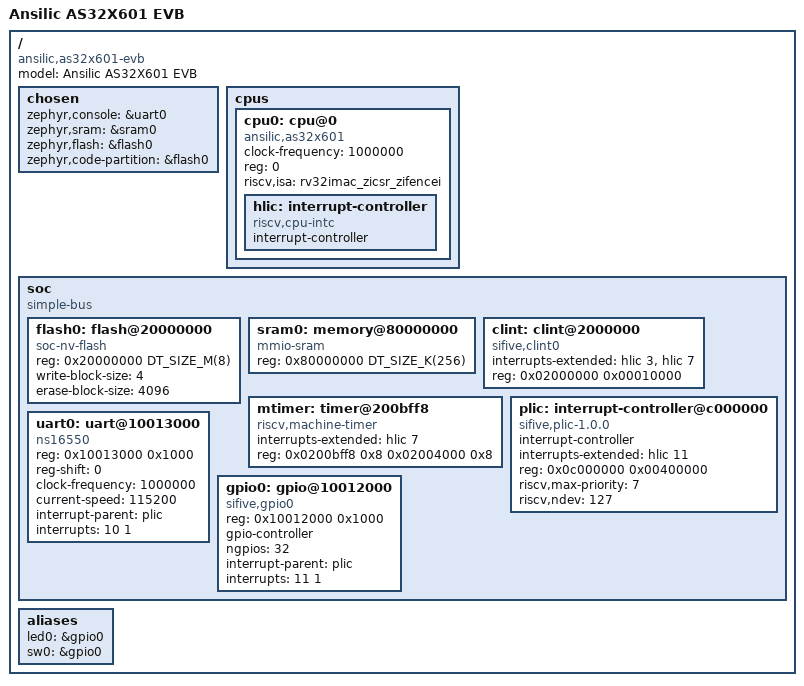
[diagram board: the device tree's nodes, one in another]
/dts-v1/;

#include <mem.h>

/ {
	model = "Ansilic AS32X601 EVB";
	compatible = "ansilic,as32x601-evb";

	#address-cells = <1>;
	#size-cells = <1>;

	chosen {
		zephyr,console = &uart0;
		zephyr,sram = &sram0;
		zephyr,flash = &flash0;
		zephyr,code-partition = &flash0;
	};

	cpus {
		#address-cells = <1>;
		#size-cells = <0>;

		cpu0: cpu@0 {
			clock-frequency = <1000000>;
			compatible = "ansilic,as32x601", "riscv";
			device_type = "cpu";
			reg = <0>;
			riscv,isa = "rv32imac_zicsr_zifencei";

			hlic: interrupt-controller {
				compatible = "riscv,cpu-intc";
				#address-cells = <0>;
				#interrupt-cells = <1>;
				interrupt-controller;
			};
		};
	};

	soc {
		#address-cells = <1>;
		#size-cells = <1>;
		compatible = "simple-bus";
		ranges;

		flash0: flash@20000000 {
			compatible = "soc-nv-flash";
			reg = <0x20000000 DT_SIZE_M(8)>;
			write-block-size = <4>;
			erase-block-size = <4096>;
			status = "okay";
		};

		sram0: memory@80000000 {
			compatible = "mmio-sram";
			reg = <0x80000000 DT_SIZE_K(256)>;
		};

		clint: clint@2000000 {
			compatible = "sifive,clint0";
			interrupts-extended = <&hlic 3>, <&hlic 7>;
			reg = <0x02000000 0x00010000>;
			status = "okay";
		};

		mtimer: timer@200bff8 {
			compatible = "riscv,machine-timer";
			interrupts-extended = <&hlic 7>;
			reg = <0x0200bff8 0x8 0x02004000 0x8>;
			reg-names = "mtime", "mtimecmp";
			status = "okay";
		};

		plic: interrupt-controller@c000000 {
			compatible = "sifive,plic-1.0.0";
			#address-cells = <0>;
			#interrupt-cells = <2>;
			interrupt-controller;
			interrupts-extended = <&hlic 11>;
			reg = <0x0c000000 0x00400000>;
			riscv,max-priority = <7>;
			riscv,ndev = <127>;
			status = "okay";
		};

		uart0: uart@10013000 {
			compatible = "ns16550";
			reg = <0x10013000 0x1000>;
			reg-shift = <0>;
			clock-frequency = <1000000>;
			current-speed = <115200>;
			interrupt-parent = <&plic>;
			interrupts = <10 1>;
			status = "okay";
		};

		gpio0: gpio@10012000 {
			compatible = "sifive,gpio0";
			reg = <0x10012000 0x1000>;
			gpio-controller;
			#gpio-cells = <2>;
			ngpios = <32>;
			interrupt-parent = <&plic>;
			interrupts = <11 1>;
			status = "okay";
		};
	};

	aliases {
		led0 = &gpio0;
		sw0 = &gpio0;
	};
};
